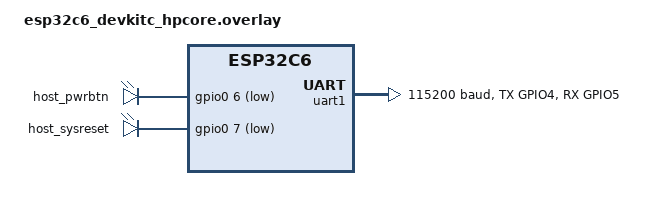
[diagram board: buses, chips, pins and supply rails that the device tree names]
/*
 * SPDX-FileCopyrightText: © 2025-2026 Tenstorrent USA, Inc.
 * SPDX-License-Identifier: Apache-2.0
 *
 * ESP32-C6 DevKitC port.
 *
 * UART0 (GPIO16/17) is the BMC console (already configured by the board DTS).
 * UART1 is wired up here for the host serial bridge:
 *   J1 pin 4 = GPIO4 = TX (out to host RX)
 *   J1 pin 5 = GPIO5 = RX (in from host TX)
 *   Common GND with the host board.
 *
 * /jtag node omitted -> CONFIG_JTAG auto-disabled via dt_path_enabled().
 * status-led alias omitted -> power.c falls back to a no-op status_led_init().
 */

#include <zephyr/dt-bindings/gpio/gpio.h>
#include <zephyr/dt-bindings/pinctrl/esp-pinctrl-common.h>
#include <zephyr/dt-bindings/pinctrl/esp32c6-pinctrl.h>
#include <zephyr/dt-bindings/pinctrl/esp32c6-gpio-sigmap.h>

/ {
	host_power {
		compatible = "gpio-leds";

		/*
		 * Host power button and system reset. Open-drain + active-low:
		 * the ESP32 only ever sinks current; the host's internal pull-up
		 * sets the un-asserted level. host_pwrbtn is pulsed by power.c
		 * when CONFIG_APP_HOST_POWER_PULSE=y. host_sysreset is pulsed by
		 * the `reset` shell command (power_reset()) for ~1 s.
		 */
		host_pwrbtn: host_pwrbtn {
			gpios = <&gpio0 6 (GPIO_ACTIVE_LOW | GPIO_OPEN_DRAIN)>;
		};
		host_sysreset: host_sysreset {
			gpios = <&gpio0 7 (GPIO_ACTIVE_LOW | GPIO_OPEN_DRAIN)>;
		};
	};

	aliases {
		reset-button = &user_button1;
		host-console-uart = &uart1;
		power-gpio-1 = &host_pwrbtn;
		reset-gpio-1 = &host_sysreset;
	};
};

&pinctrl {
	uart1_default: uart1_default {
		group1 {
			pinmux = <UART1_TX_GPIO4>;
			output-high;
		};
		group2 {
			pinmux = <UART1_RX_GPIO5>;
			bias-pull-up;
		};
	};
};

&dma {
	status = "okay";
};

&uart1 {
	status = "okay";
	current-speed = <115200>;
	pinctrl-0 = <&uart1_default>;
	pinctrl-names = "default";
	/* GDMA channels for async TX / RX. Channels 2,3 are reserved by i2s
	 * in the SoC DTS (i2s itself is disabled in this build).
	 */
	dmas = <&dma 0>, <&dma 1>;
	dma-names = "tx", "rx";
};
